# STM32N647xx register map
File version: 1.0
Registers are 32-bit, read-write, reset 0x0 unless marked. A register's access mark holds for its fields unless they carry their own. Offsets are from the block's base; [hi:lo] are bit positions; {n}, {i} and the like mark numbered series.

## IWDG
Base 0x46004800
0x00 KR — IWDG key register
  [15:0] KEY — Key value (write only, read 0x0000)
0x04 PR — IWDG prescaler register
  [3:0] PR — Prescaler divider
0x08 RLR — IWDG reload register
  [11:0] RL — Watchdog counter reload value
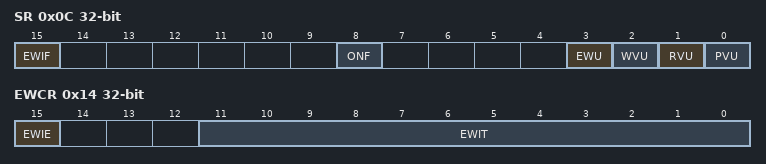
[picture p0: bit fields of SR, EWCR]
0x0C SR — IWDG status register
  [15] EWIF — Watchdog Early Interrupt flag
  [8] ONF — Watchdog Enable status bit
  [3] EWU — Watchdog interrupt comparator value update
  [2] WVU — Watchdog counter window value update
  [1] RVU — Watchdog counter reload value update
  [0] PVU — Watchdog prescaler value update
0x10 WINR — IWDG window register
  [11:0] WIN — Watchdog counter window value
0x14 EWCR — IWDG early wakeup interrupt register
  [15] EWIE — Watchdog early interrupt enable
  [11:0] EWIT — Watchdog counter window value
0x18 ICR — IWDG interrupt clear register
  [15] EWIC — Watchdog early interrupt acknowledge

## BSEC — Boot and Security
Base 0x46009000
{0x0+4i} FVRw{i} (i=0..383) — BSEC fuse word (0-383) value register
  [31:0] FV — Fuse value
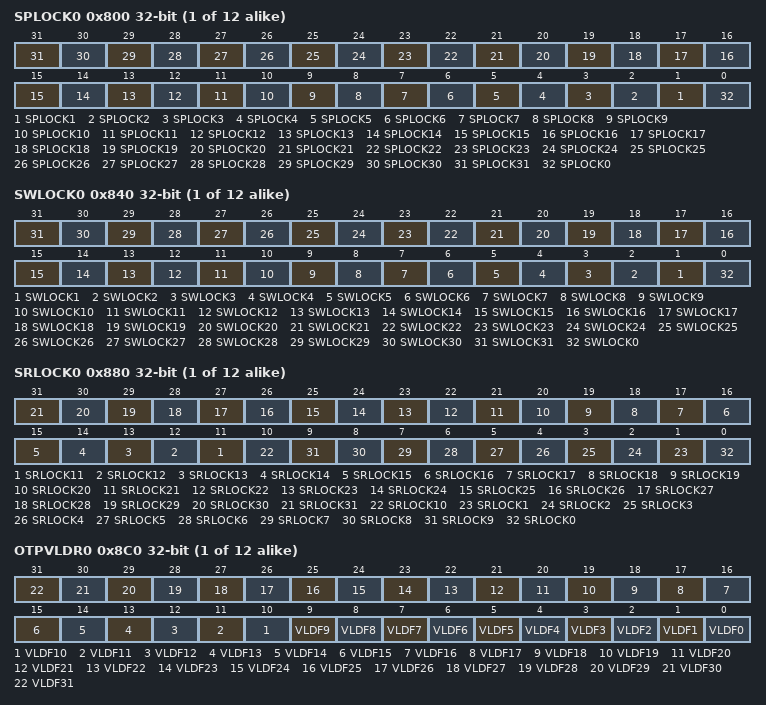
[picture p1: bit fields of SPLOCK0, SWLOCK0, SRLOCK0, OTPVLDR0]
{0x800+4i} SPLOCK{i} (i=0..11) — BSEC sticky program lock register (0-11)
  [n] SPLOCK{n} (n=1..31) — Sticky programming lock for word ({n}+32 x)
  [0] SPLOCK0 — Sticky programming lock for word (32 x)
{0x840+4i} SWLOCK{i} (i=0..11) — BSEC sticky write lock register (0-11)
  [n] SWLOCK{n} (n=1..31) — Sticky write lock for shadow register ({n}+32 x)
  [0] SWLOCK0 — Sticky write lock for shadow register (32 x)
{0x880+4i} SRLOCK{i} (i=0..11) — BSEC sticky reload lock register (0-11)
  [n] SRLOCK{n} (n=11..31) — Sticky reload lock for fuse word ({n}+32 x)
  [10] SRLOCK10 — Sticky reload lock for fuse word (10+2 x)
  [n] SRLOCK{n} (n=1..9) — Sticky reload lock for fuse word ({n}+32 x)
  [0] SRLOCK0 — Sticky reload lock for fuse word (32 x)
{0x8C0+4i} OTPVLDR{i} (i=0..11) — BSEC OTP valid register (0-11)
  [n] VLDF{n} (n=1..31) — Valid flag for shadow register ({n}+32 x)
  [0] VLDF0 — Valid flag for shadow register (32 x)
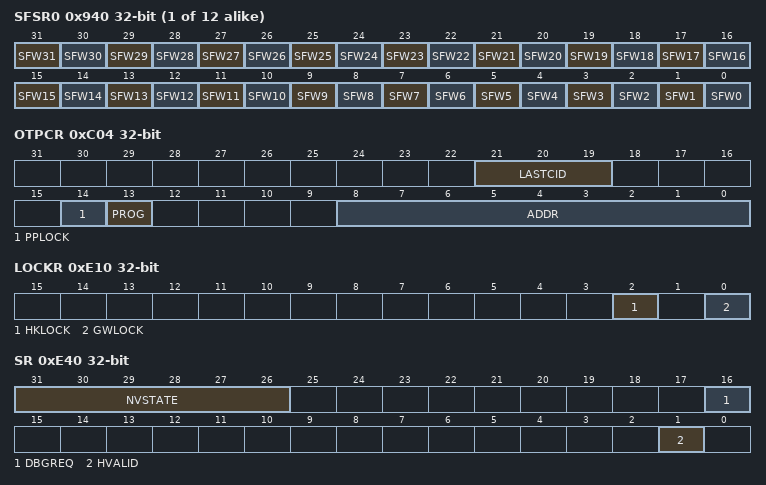
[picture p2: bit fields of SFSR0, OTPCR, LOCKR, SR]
{0x940+4i} SFSR{i} (i=0..11) — BSEC shadowed fuses status register (0-11)
  [n] SFW{n} (n=1..31) — Shadowed fuse word ({n}+32 x)
  [0] SFW0 — Shadowed fuse word (32 x)
0xC04 OTPCR — BSEC OTP control register
  [21:19] LASTCID
  [14] PPLOCK — Permanent programming lock
  [13] PROG — Fuse word programming
  [8:0] ADDR — Fuse word address
0xC08 WDR — BSEC write data register
  [31:0] WRDATA — OTP write data
{0xE00+4i} SCRATCHR{i} (i=0..3) — BSEC scratch register (0-3)
  [31:0] SDATA — Scratch data
0xE10 LOCKR — BSEC lock register
  [2] HKLOCK — Hardware key lock
  [0] GWLOCK — Global write lock
0xE14 JTAGINR — BSEC JTAG input register
  [31:0] JDATAIN — JTAG input data
0xE18 JTAGOUTR — BSEC JTAG output register
  [31:0] JDATAOUT — JTAG output data
0xE24 UNMAPR — BSEC unmap register
  [31:0] UNMAP — Unmap key
0xE40 SR — BSEC status register
  [31:26] NVSTATE — Non-volatile state
  [16] DBGREQ — Debug request
  [1] HVALID — Hardware key valid
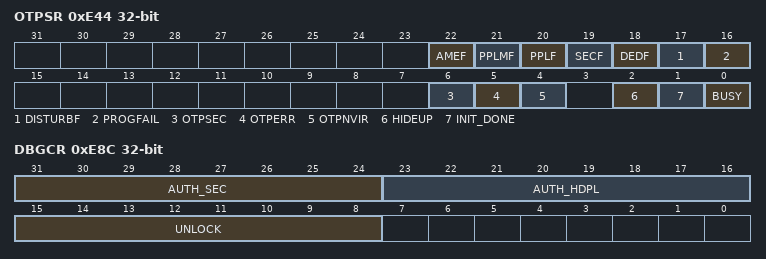
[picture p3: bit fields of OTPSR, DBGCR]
0xE44 OTPSR — BSEC OTP status register
  [22] AMEF — Addresses mismatch error flag
  [21] PPLMF — Permanent programming lock mismatch flag
  [20] PPLF — Permanent programming lock flag
  [19] SECF — Single error correction flag
  [18] DEDF — Double error detection flag
  [17] DISTURBF — Disturb flag
  [16] PROGFAIL — Programming failed
  [6] OTPSEC — OTP with single error correction
  [5] OTPERR — OTP with error
  [4] OTPNVIR — OTP not virgin
  [2] HIDEUP — Hide upper fuse words
  [1] INIT_DONE — Initialization done
  [0] BUSY — Busy flag
0xE80 EPOCHR0 — BSEC epoch register (0-1)
  [31:0] EPOCH
0xE84 EPOCHR1 — BSEC epoch register (0-1)
  [31:0] EPOCH
0xE88 EPOCHSELR — BSEC epoch select register
  [0] EPSEL — Epoch selection
0xE8C DBGCR — BSEC debug control register
  [31:24] AUTH_SEC — Secure debug authorization
  [23:16] AUTH_HDPL — Level at which debug may be opened
  [15:8] UNLOCK — Non-secure debug authorization
0xE90 AP_UNLOCK — BSEC AP unlock
  [7:0] UNLOCK — Unlock DBG_MCU AP interface
0xE94 HDPLSR — BSEC hide protection level status register
  [7:0] HDPL — Current HDPL
0xE98 HDPLCR — BSEC hide protection level control register
  [31:0] INCR_HDPL — Increment HDPL
0xE9C NEXTLR — BSEC next hide protection level register
  [1:0] INCR — Increment
{0xF40+4i} WOSCR{i} (i=0..7) — BSEC write once scratch register (0-7)
  [31:0] WOSDATA — Write once scratch data
0xFE8 HRCR — BSEC hot reset count register
  [31:0] HRC — Hot reset counter
0xFEC WRCR — BSEC warm reset count register
  [31:0] WRC — Warm reset counter
